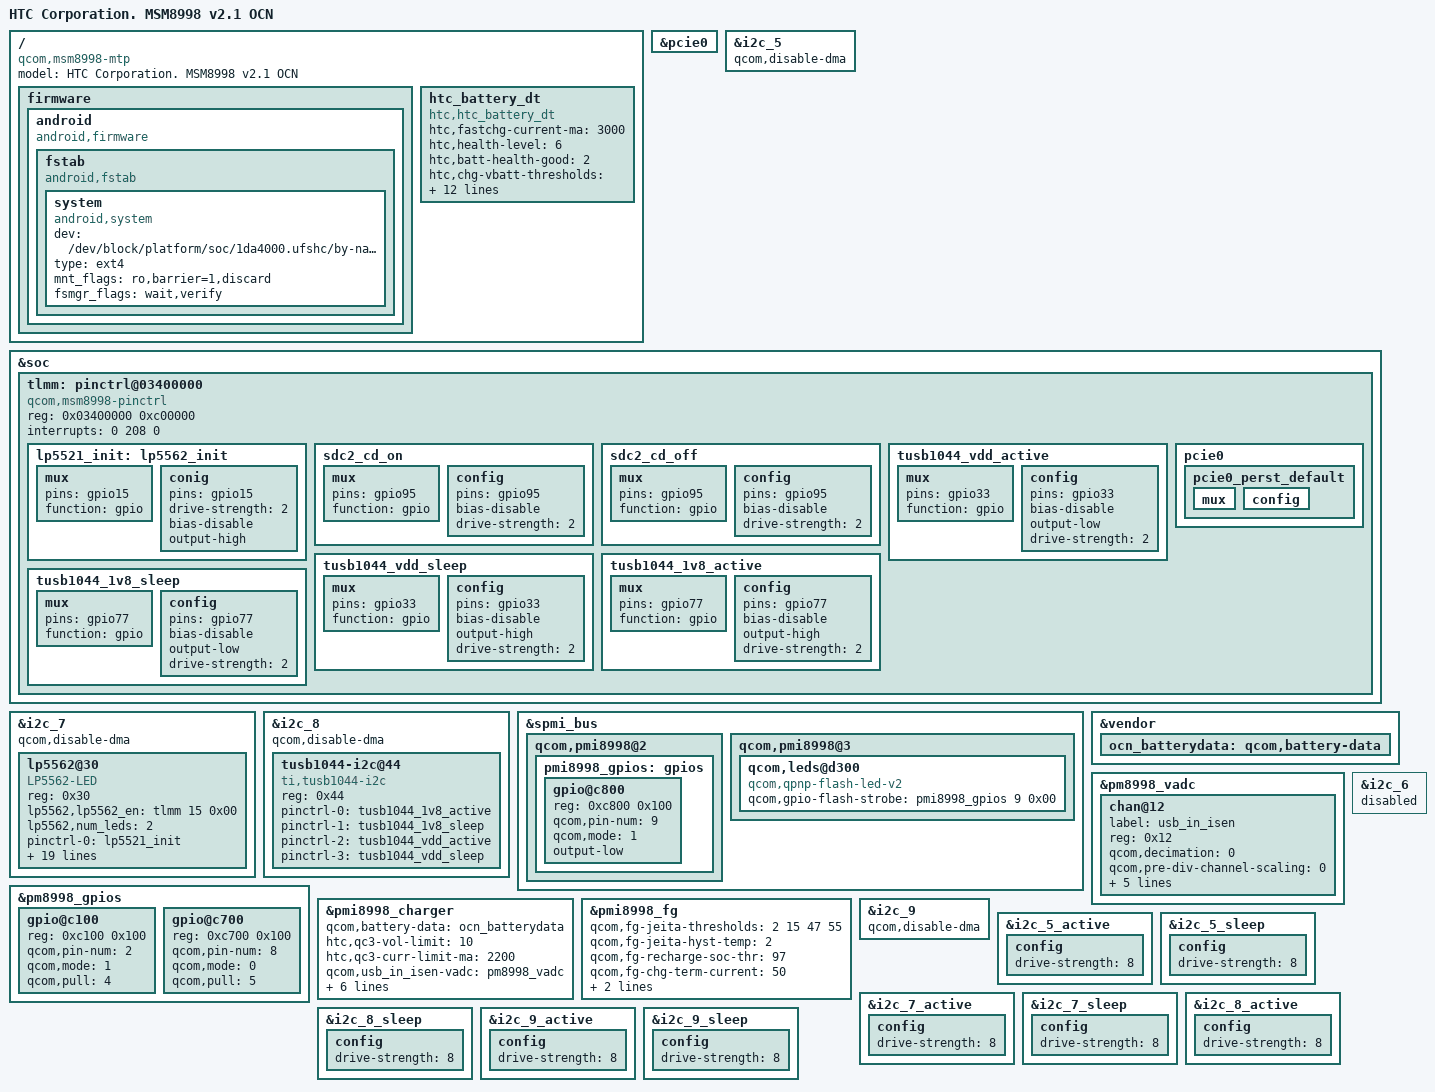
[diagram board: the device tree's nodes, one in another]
/* Copyright (c) 2016, The Linux Foundation. All rights reserved.
 *
 * This program is free software; you can redistribute it and/or modify
 * it under the terms of the GNU General Public License version 2 and
 * only version 2 as published by the Free Software Foundation.
 *
 * This program is distributed in the hope that it will be useful,
 * but WITHOUT ANY WARRANTY; without even the implied warranty of
 * MERCHANTABILITY or FITNESS FOR A PARTICULAR PURPOSE.  See the
 * GNU General Public License for more details.
 */


#include "msm8998-mtp.dtsi"
#include "msm8998-htc-common.dtsi"
#include "dsi-panel-ocn.dtsi"
#include "msm8998-audio-htc_ocn.dtsi"
#include "msm8998-key-ocn.dtsi"
#include "msm8998-htc_ocn_hall-sensor.dtsi"
#include "msm8998-htc_ocn_cap.dtsi"
#include "msm8998-htc_ocn_touch.dtsi"
#include "msm8998-htc_ocn-fingerprint.dtsi"
#include "msm8998-htc-nanohub.dtsi"
#include "msm8998-htc_ocn_nfc_nxp.dtsi"
#include "msm8998-htc_ocn_regulator.dtsi"
#include "msm8998-vibrator-ocn.dtsi"
#include "msm8998-htc_ocn_usb.dtsi"

/ {
        model = "HTC Corporation. MSM8998 v2.1 OCN";
        compatible = "qcom,msm8998-mtp", "qcom,msm8998", "qcom,mtp";
};

/ {
	firmware: firmware {
		android {
			compatible = "android,firmware";
			fstab {
				compatible = "android,fstab";
				system {
					compatible = "android,system";
					dev = "/dev/block/platform/soc/1da4000.ufshc/by-name/system";
					type = "ext4";
					mnt_flags = "ro,barrier=1,discard";
					fsmgr_flags = "wait,verify";
					status = "ok";
				};

			};
		};
	};
};

&tlmm {
		pcie0 {
			pcie0_perst_default: pcie0_perst_default {
				mux {
				/delete-property/pins;
				};

				config {
				/delete-property/pins;
				};
			};
		};
};

&pcie0 {
   /delete-property/perst-gpio;
};

&i2c_5 {
	/delete-node/ synaptics@20;
};

&soc {
	tlmm: pinctrl@03400000 {
		compatible = "qcom,msm8998-pinctrl";
		reg = <0x03400000 0xc00000>;
		interrupts = <0 208 0>;

		lp5521_init: lp5562_init {
			mux {
				pins ="gpio15";
				function = "gpio";
			};
			conig {
				pins ="gpio15";
				drive-strength = <2>; // 2 MA
				bias-disable; // No PULL
				output-high;
			};
		};

		sdc2_cd_on: sdc2_cd_on {
			mux {
				pins = "gpio95";
				function = "gpio";
			};

			config {
				pins = "gpio95";
				/delete-property/bias-pull-up;
				bias-disable;           /* no pull */
				drive-strength = <2>;   /* 2 MA */
			};
		};

		sdc2_cd_off: sdc2_cd_off {
			mux {
				pins = "gpio95";
				function = "gpio";
			};

			config {
				pins = "gpio95";
				/delete-property/bias-pull-up;
				bias-disable;           /* no pull */
				drive-strength = <2>;   /* 2 MA */
			};

		};

		tusb1044_vdd_active: tusb1044_vdd_active {
			mux {
				pins = "gpio33";
				function = "gpio";
			};

			config {
				pins = "gpio33";
				bias-disable;
				output-low;
				drive-strength = <2>;
			};
		};

		tusb1044_vdd_sleep: tusb1044_vdd_sleep {
                        mux {
                                pins = "gpio33";
                                function = "gpio";
                        };

                        config {
                                pins = "gpio33";
                                bias-disable;
                                output-high;
                                drive-strength = <2>;
                        };
		};

		tusb1044_1v8_active: tusb1044_1v8_active {
			mux {
				pins = "gpio77";
				function = "gpio";
			};

			config {
				pins = "gpio77";
				bias-disable;
				output-high;
				drive-strength = <2>;
			};
		};

		tusb1044_1v8_sleep: tusb1044_1v8_sleep {
			mux {
                                pins = "gpio77";
                                function = "gpio";
                        };

                        config {
                                pins = "gpio77";
                                bias-disable;
                                output-low;
                                drive-strength = <2>;
                        };
                };
	};
};

&i2c_7 {
	lp5562@30 {
		compatible = "LP5562-LED";
		reg = <0x30>;
		lp5562,lp5562_en = <&tlmm 15 0x00>;
//		lp5562,LED_3v3_en = <&pm8998_gpios 6 0x00>; USB config 3V3 in SBL
		lp5562,num_leds = <2>;
		pinctrl-names = "lp5562_init";
		pinctrl-0 = <&lp5521_init>;
		lp5562,current_param = <150>;
		lp5562,vk_use;
		lp5562,vk_current_param = <200>;
		vk-pwm-array = [00 20 70 70 B0 B0 FF FF FF FF FF];
		vk-black-cg-id-def = "DEF00", "GRY00", "LOB00", "BLK00";
		vk-white-cg-id-def = "PNK00", "GOD00", "LOW00", "WHT00";
		vk-black-pwm-array-def = [00 10 40 40 40 40 90 90 90 90 90 FF FF FF FF FF];
		vk-white-pwm-array-def = [00 10 40 40 40 40 90 90 90 90 90 FF FF FF FF FF];
		vk-current-array-def =   [64 64 64 64 64 64 FF FF FF FF FF FF FF FF FF FF];
		vk-black-pwm-array-sec = [00 10 40 40 40 40 90 90 90 90 90 FF FF FF FF FF];
		vk-white-pwm-array-sec = [00 10 40 40 40 40 90 90 90 90 90 FF FF FF FF FF];
		vk-current-array-sec =   [64 64 64 64 64 64 FF FF FF FF FF FF FF FF FF FF];
	};
};

&i2c_8 {
	tusb1044-i2c@44 {
		compatible = "ti,tusb1044-i2c";
		reg = <0x44>;
		pinctrl-names = "pin_active", "pin_sleep", "vdd_pin_active", "vdd_pin_sleep";
		pinctrl-0 = <&tusb1044_1v8_active>;
		pinctrl-1 = <&tusb1044_1v8_sleep>;
		pinctrl-2 = <&tusb1044_vdd_active>;
		pinctrl-3 = <&tusb1044_vdd_sleep>;
	};
};

&spmi_bus {
	qcom,pmi8998@2 {
		pmi8998_gpios: gpios {
			gpio@c800 {
				reg = <0xc800 0x100>;
				qcom,pin-num = <9>;
				qcom,mode = <1>;
				output-low;
				status = "okay";
			};
		};
	};
	qcom,pmi8998@3 {
		qcom,leds@d300 {
			compatible = "qcom,qpnp-flash-led-v2";
			qcom,gpio-flash-strobe = <&pmi8998_gpios 9 0x00>;
		};
	};
};

&vendor {
	ocn_batterydata: qcom,battery-data {
		/delete-node/ qcom,itech_3000mah;
		/delete-node/ qcom,ascent_3450mah;
		/delete-node/ qcom,demo_6000mah;
		#include "batterydata-ocn-id1.dtsi"
		#include "batterydata-ocn-id2.dtsi"
		#include "batterydata-ocn-semi.dtsi"
		#include "batterydata-ocn-unknown.dtsi"
	};
};

&pm8998_vadc {
	chan@12 {
		label = "usb_in_isen";
		reg = <0x12>;
		qcom,decimation = <0>;
		qcom,pre-div-channel-scaling = <0>;
		qcom,calibration-type = "ratiometric";
		qcom,scale-function = <0>;
		qcom,hw-settle-time = <1>;
		qcom,fast-avg-setup = <2>;
		qcom,cal-val = <0>;
	};
};

&pm8998_gpios {
	gpio@c100 {
		reg = <0xc100 0x100>;
		qcom,pin-num = <2>;
		status = "okay";
		qcom,mode = <1>;
		qcom,pull = <4>;
	};
	gpio@c700 {
		reg = <0xc700 0x100>;
		qcom,pin-num = <8>;
		qcom,mode = <0>;
		qcom,pull = <5>;
		status = "okay";
        };

};

&pmi8998_charger {
	qcom,battery-data = <&ocn_batterydata>;
	htc,qc3-vol-limit = <10>;
	htc,qc3-curr-limit-ma = <2200>;
	qcom,usb_in_isen-vadc = <&pm8998_vadc>;
	qcom,usb_in_isen-channel = <0x12>; //MPP2
	iusb_rsen = <1400>;
	iusb_multiplier = <2050>;
	htc,htc-chg-ready = <&tlmm 128 0>;
	htc,htc-chg-enable  = <&pm8998_gpios 2 0>;
	qcom,auto-recharge-soc;
};

&pmi8998_fg {
	qcom,fg-jeita-thresholds = <2 15 47 55>;
	qcom,fg-jeita-hyst-temp = <2>;
	qcom,fg-recharge-soc-thr = <97>;
	qcom,fg-chg-term-current = <50>;
	qcom,fg-cutoff-voltage = <3400>;
	qcom,fg-rsense-sel = <0>;
};

/ {
	htc_battery_dt {
		compatible = "htc,htc_battery_dt";
		htc,fastchg-current-ma = <3000>;
		htc,health-level = <6>;
		htc,batt-health-good = <2>;
		htc,chg-vbatt-thresholds = <4250 4250 4250 4250 4250 4250>;	/* htc,health-level * 1 */
		htc,chg-vbatt-recover-thresholds = <4000 4000 4000 4000 4000 4000>;
		htc,chg-temp-thresholds = <(-10000) 170>,			/* htc,health-level * 2 */
					  <     150 220>,
					  <     420 200>,			/* GOOD */
					  <     450 400>,
					  <     470 430>,
					  <   10000 450>;
		htc,chg-fcc-limits = <						/* 4 * htc,health-level */
			1500 3000 3000 3000 1500 1500
			1500 3000 3000 1000 1000 1000
			 900 3000 3000 3000 1500    0
			 900 3000 3000 1000 1000    0
		>;
		htc,qc2-chg-fcc-limits = <					/* 4 * htc,health-level */
			1500 3000 3000 2000 1500 1500
			1500 3000 3000 1000 1000 1000
			 900 1500 2100 2000 1500    0
			 900 1500 2100 1000 1000    0
		>;
		htc,qc3-chg-fcc-limits = <					/* 4 * htc,health-level */
			1500 3000 3000 2100 1500 1500
			1500 3000 3000 2100 1500 1500
			 900 1500 2100 2100 1500    0
			 900 1500 2100 2100 1500    0
		>;
	};
};

&i2c_5 {
	status = "okay";
	qcom,disable-dma;
};

&i2c_6 {
	status = "disabled";
	/delete-node/ nq@28;
};

&i2c_7 {
	status = "okay";
	qcom,disable-dma;
	/delete-node/ qcom,smb138x@8;
};

&i2c_8 {
	status = "okay";
	qcom,disable-dma;
};

&i2c_9 {
	status = "okay";
	qcom,disable-dma;
};

&i2c_5_active {
	config {
		drive-strength = <8>;
	};
};
&i2c_5_sleep {
	config {
		drive-strength = <8>;
	};
};

&i2c_7_active {
	config {
		drive-strength = <8>;
	};
};
&i2c_7_sleep {
	config {
		drive-strength = <8>;
	};
};

&i2c_8_active {
	config {
		drive-strength = <8>;
	};
};
&i2c_8_sleep {
	config {
		drive-strength = <8>;
	};
};

&i2c_9_active {
	config {
		drive-strength = <8>;
	};
};
&i2c_9_sleep {
	config {
		drive-strength = <8>;
	};
};
